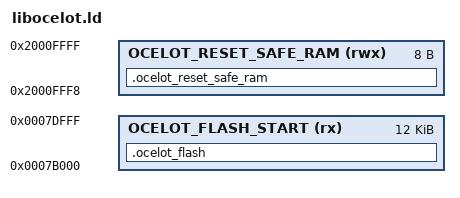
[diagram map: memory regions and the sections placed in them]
/* This file is automatically generated.  Do not modify.*/

MEMORY
{
   OCELOT_FLASH_START (rx) : ORIGIN = 0x7B000, LENGTH = 0x3000
   OCELOT_RESET_SAFE_RAM (rwx) : ORIGIN = 0x2000FFF8, LENGTH = 0x8
}

SECTIONS
{
   .ocelot_flash (NOLOAD):
   {
      *(.ocelot_flash)
   } > OCELOT_FLASH_START
   .ocelot_reset_safe_ram (COPY):
   {
      . = ALIGN(4);
      *(.ocelot_reset_safe_ram)
   } > OCELOT_RESET_SAFE_RAM
}
